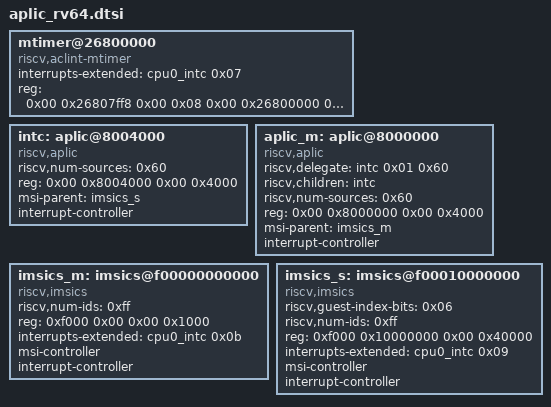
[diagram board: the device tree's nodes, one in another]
		mtimer@26800000 {
			interrupts-extended = <&cpu0_intc 0x07>;
			reg = <0x00 0x26807ff8 0x00 0x08 0x00 0x26800000 0x00 0x7ff8>;
			compatible = "riscv,aclint-mtimer";
		};

		intc: aplic@8004000 {
			riscv,num-sources = <0x60>;
			reg = <0x00 0x8004000 0x00 0x4000>;
			msi-parent = <&imsics_s>;
			interrupt-controller;
			#interrupt-cells = <0x02>;
			compatible = "riscv,aplic";
		};

		aplic_m: aplic@8000000 {
			riscv,delegate = <&intc 0x01 0x60>;
			riscv,children = <&intc>;
			riscv,num-sources = <0x60>;
			reg = <0x00 0x8000000 0x00 0x4000>;
			msi-parent = <&imsics_m>;
			interrupt-controller;
			#interrupt-cells = <0x02>;
			compatible = "riscv,aplic";
		};

		imsics_m: imsics@f00000000000 {
			riscv,num-ids = <0xff>;
			reg = <0xf000 0x00 0x00 0x1000>;
			interrupts-extended = <&cpu0_intc 0x0b>;
			msi-controller;
			interrupt-controller;
			#interrupt-cells = <0x00>;
			compatible = "riscv,imsics";
		};

		imsics_s: imsics@f00010000000 {
			riscv,guest-index-bits = <0x06>;
			riscv,num-ids = <0xff>;
			reg = <0xf000 0x10000000 0x00 0x40000>;
			interrupts-extended = <&cpu0_intc 0x09>;
			msi-controller;
			interrupt-controller;
			#interrupt-cells = <0x00>;
			compatible = "riscv,imsics";
		};
